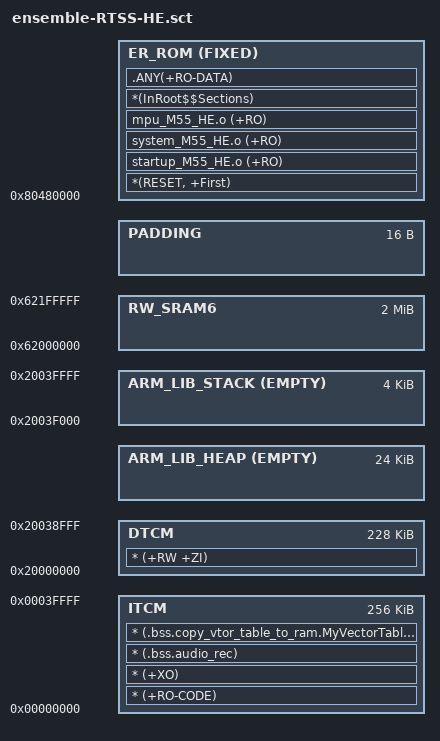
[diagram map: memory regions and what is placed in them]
#! armclang -E --target=arm-arm-none-eabi -mcpu=cortex-m55 -xc
; command above MUST be in first line (no comment above!)

;/* Copyright (C) 2022 Alif Semiconductor - All Rights Reserved.
; * Use, distribution and modification of this code is permitted under the
; * terms stated in the Alif Semiconductor Software License Agreement
; *
; * You should have received a copy of the Alif Semiconductor Software
; * License Agreement with this file. If not, please write to:
; * contact@alifsemi.com, or visit: https://alifsemi.com/license
; *
; */

/*On chip RAM Regions */
#define SRAM0_BASE                0x02000000
#define SRAM0_SIZE                0x00400000		/* 4M */
#define SRAM1_BASE                0x08000000
#define SRAM1_SIZE                0x00280000		/* 2.5M */
#define SRAM2_BASE                0x50000000
#define SRAM2_SIZE                0x00040000		/* 256K */
#define SRAM3_BASE                0x50800000
#define SRAM3_SIZE                0x00100000		/* 1M */
#define SRAM4_BASE                0x60000000
#define SRAM4_SIZE                0x00040000		/* 256K */
#define SRAM5_BASE                0x60800000
#define SRAM5_SIZE                0x00040000		/* 256K */
#define SRAM6_BASE                0x62000000
#define SRAM6_SIZE                0x00200000		/* 2M */
#define SRAM7_BASE                0x63000000
#define SRAM7_SIZE                0x00080000		/* 512K */
#define SRAM8_BASE                0x63100000
#define SRAM8_SIZE                0x00200000		/* 2M */
#define SRAM9_BASE                0x64000000
#define SRAM9_SIZE                0x000C0000		/* 768K */
/* On Chip NVM */
#define MRAM_BASE                 0x80000000
#define MRAM_SIZE                 0x00580000		/* 5.5M */

/*--------------------- ITCM Configuration ----------------------------------*/
/* SRAM4 is mapped as ITCM */
#define ITCM_BASE                 0x00000000
#define ITCM_SIZE                 SRAM4_SIZE /* 256K */
#define ITCM_GLOBAL_BASE          SRAM4_BASE

/*--------------------- DTCM Configuration ---------------------------*/
/* SRAM5 is mapped as DTCM */
#define DTCM_BASE                 0x20000000
#define DTCM_SIZE                 SRAM5_SIZE /* 256KB */
#define DTCM_GLOBAL_BASE          SRAM5_BASE

#define __STACK_SIZE    0x00001000
#define __HEAP_SIZE     0x00006000

;----------------------------------------------------------------------------
;   User Stack & Heap boundary definition
;----------------------------------------------------------------------------
#define __STACK_TOP     (DTCM_BASE + DTCM_SIZE)   /* starts at end of RAM */
#define __HEAP_BASE     (AlignExpr(+0, 8))            /* starts after RW_RAM section, 8 byte aligned */

;----------------------------------------------------------------------------
;  Scatter File Definitions definition
;----------------------------------------------------------------------------
#define __RO_BASE       0x80480000
#define __RO_SIZE       0xFF000

#define __RW_BASE       DTCM_BASE
#define __RW_SIZE      (DTCM_SIZE - __STACK_SIZE - __HEAP_SIZE)


LR_ROM __RO_BASE __RO_SIZE  {                       ; load region size_region
  ER_ROM +0 FIXED {                                 ; load address = execution address
   ; MRAM has start-up code, and most constant data
   *(RESET, +First)
   startup_M55_HE.o (+RO)
   system_M55_HE.o (+RO)
   mpu_M55_HE.o (+RO)
   *(InRoot$$Sections)
   .ANY(+RO-DATA)
  }

  ITCM ITCM_BASE ITCM_SIZE {  ; --------------------------------
      ; ITCM has non-startup code, audio record buffer and RAM vectors
      * (+RO-CODE)
      * (+XO)
      * (.bss.audio_rec)
      * (.bss.copy_vtor_table_to_ram.MyVectorTable)
  }

  ;-----------------------------------------------------
  ; R/W region - remaining part of the 256KiB RAM region
  ; Other parts of this region used up by stack + heap.
  ;-----------------------------------------------------
  DTCM __RW_BASE __RW_SIZE  {  ; RW data in DTCM
      ; DTCM has all read-write data,
      ; including NPU activation buffer and audio processing buffers
      * (+RW +ZI)
  }

  ARM_LIB_HEAP  __HEAP_BASE EMPTY  __HEAP_SIZE  {  }
  ARM_LIB_STACK __STACK_TOP EMPTY -__STACK_SIZE {  }

  RW_SRAM6 SRAM6_BASE ALIGN 16 SRAM6_SIZE  {  ; 2MB ----------------------------
  }

  PADDING +0 ALIGN 16 FILL 0 16  {  }
}

#if 0
#define _PARTITION_ADDRESS          0x8057F000
#define _PARTITION_SIZE             0x1000

LR_PARTITION _PARTITION_ADDRESS  _PARTITION_SIZE
{
	RESERVED +0 FILL 0 (_PARTITION_SIZE - 16) {}
	ATOC +0 16 { *(:gdef:__mram_atoc) }
}
#endif
